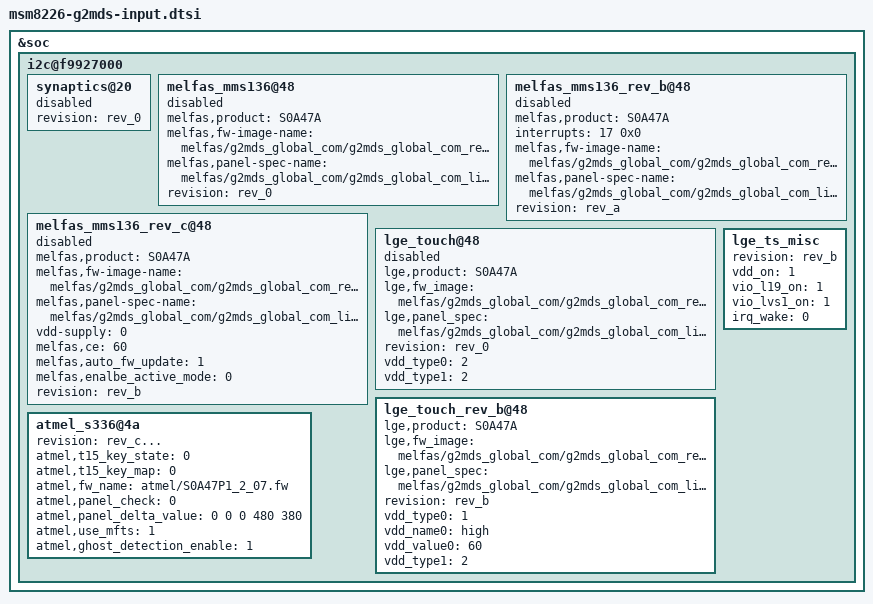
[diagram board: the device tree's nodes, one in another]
/* Copyright (c) 2013, LGE Electronics. All rights reserved.
 *
 * This program is free software; you can redistribute it and/or modify
 * it under the terms of the GNU General Public License version 2 and
 * only version 2 as published by the Free Software Foundation.
 *
 * This program is distributed in the hope that it will be useful,
 * but WITHOUT ANY WARRANTY; without even the implied warranty of
 * MERCHANTABILITY or FITNESS FOR A PARTICULAR PURPOSE.  See the
 * GNU General Public License for more details.
 */

&soc {
	i2c@f9927000 { /* BLSP1 QUP5 */
		synaptics@20 {
			//synaptics,fw-image-name = "synaptics/PR1237618-DS4.3.5.0.16.img";
			revision = "rev_0";
			status = "disable";
		};
		melfas_mms136@48 {
			melfas,product = "S0A47A";
			melfas,fw-image-name = "melfas/g2mds_global_com/g2mds_global_com_rev_a_v101.mfsb";
			melfas,panel-spec-name = "melfas/g2mds_global_com/g2mds_global_com_limit.txt";
			revision = "rev_0";
			status = "disable";
		};
		melfas_mms136_rev_b@48 {
			melfas,product = "S0A47A";
			interrupts = <17 0x0>;
			melfas,fw-image-name = "melfas/g2mds_global_com/g2mds_global_com_rev_a_v101.mfsb";
			melfas,panel-spec-name = "melfas/g2mds_global_com/g2mds_global_com_limit.txt";
			revision = "rev_a";
			status = "disable";
		};
		melfas_mms136_rev_c@48 {
			melfas,product = "S0A47A";
			melfas,fw-image-name = "melfas/g2mds_global_com/g2mds_global_com_rev_a_v101.mfsb";
			melfas,panel-spec-name = "melfas/g2mds_global_com/g2mds_global_com_limit.txt";
			vdd-supply = <0>;
			melfas,ce = <60>;
			melfas,auto_fw_update = <1>;
			melfas,enalbe_active_mode = <0>;
			revision = "rev_b";
			status ="disable";
		};
		lge_touch@48 {
			lge,product = "S0A47A";
			lge,fw_image = "melfas/g2mds_global_com/g2mds_global_com_rev_a_v101.mfsb";
			lge,panel_spec = "melfas/g2mds_global_com/g2mds_global_com_limit.txt";
			revision = "rev_0";
			status = "disable";
			vdd_type0 = <2>;
			vdd_type1 = <2>;
		};

		lge_touch_rev_b@48 {
			lge,product = "S0A47A";
			lge,fw_image = "melfas/g2mds_global_com/g2mds_global_com_rev_a_v101.mfsb";
			lge,panel_spec = "melfas/g2mds_global_com/g2mds_global_com_limit.txt";
			revision = "rev_b";
			status = "ok";
			vdd_type0 = <1>;
			vdd_name0 = "high";
			vdd_value0 = <60>;
			vdd_type1 = <2>;
		};

		atmel_s336@4a {
			revision = "rev_c...";
			status = "ok";
			atmel,t15_key_state = <0>;
			atmel,t15_key_map = <0>;
			atmel,fw_name = "atmel/S0A47P1_2_07.fw";
			atmel,panel_check = <0>;
			atmel,panel_delta_value = <0 0 0 480 380>;
			atmel,use_mfts = <1>;
			atmel,ghost_detection_enable = <1>;
		};

		lge_ts_misc {
			revision = "rev_b";
			vdd_on = <1>;
			vio_l19_on = <1>;
			vio_lvs1_on = <1>;
			irq_wake = <0>;
			status ="ok";
		};
	};
};
